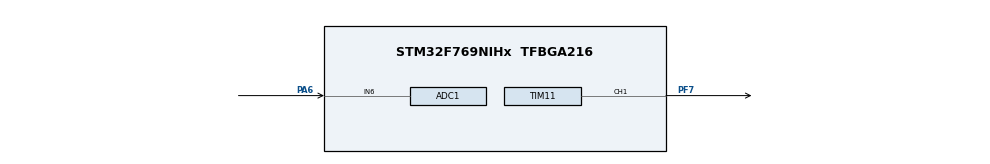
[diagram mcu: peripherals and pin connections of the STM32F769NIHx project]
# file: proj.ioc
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ADC1.Channel-1\#ChannelRegularConversion=ADC_CHANNEL_6
ADC1.NbrOfConversionFlag=1
ADC1.Rank-1\#ChannelRegularConversion=1
ADC1.SamplingTime-1\#ChannelRegularConversion=ADC_SAMPLETIME_3CYCLES
ADC1.master=1
Mcu.Family=STM32F7
Mcu.Name=STM32F769NIHx
Mcu.Package=TFBGA216
NVIC.ADC_IRQn=true\:0\:0\:false\:false\:true\:true\:true
NVIC.PriorityGroup=NVIC_PRIORITYGROUP_4
NVIC.TIM1_TRG_COM_TIM11_IRQn=true\:0\:0\:false\:false\:true\:true\:true
PA6.GPIO_PuPd=GPIO_NOPULL
PA6.Signal=SharedAnalog_PA6
PF7.GPIO_Speed=GPIO_SPEED_FREQ_LOW
PF7.Signal=S_TIM11_CH1
ProjectManager.HeapSize=0x200
ProjectManager.StackSize=0x400
ProjectManager.TargetToolchain=STM32CubeIDE
RCC.HSE_VALUE=25000000
RCC.HSI_VALUE=16000000
RCC.LSE_VALUE=32768
RCC.USBFreq_Value=96000000
RCC.VCOOutputFreq_Value=192000000
SH.S_TIM11_CH1.0=TIM11_CH1,PWM Generation1 CH1
SH.SharedAnalog_PA6.0=GPIO_Analog
SH.SharedAnalog_PA6.1=ADC1_IN6,IN6
TIM11.Channel=TIM_CHANNEL_1
TIM11.Period=100
TIM11.Prescaler=500
VP_TIM11_VS_ClockSourceINT.Mode=Enable_Timer
board=custom

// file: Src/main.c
/* USER CODE BEGIN Header */
/**
  ******************************************************************************
  * @file           : main.c
  * @brief          : Main program body
  ******************************************************************************
  * @attention
  *
  * <h2><center>&copy; Copyright (c) 2019 STMicroelectronics.
  * All rights reserved.</center></h2>
  *
  * This software component is licensed by ST under BSD 3-Clause license,
  * the "License"; You may not use this file except in compliance with the
  * License. You may obtain a copy of the License at:
  *                        opensource.org/licenses/BSD-3-Clause
  *
  ******************************************************************************
  */
/* USER CODE END Header */

#include "main.h"

ADC_HandleTypeDef hadc1;
float dutyCycle;
TIM_HandleTypeDef htim11;

void SystemClock_Config(void);
static void MX_GPIO_Init(void);
static void MX_ADC1_Init(void);
static void MX_TIM11_Init(void);

int main(void)
{

  /* MCU Configuration--------------------------------------------------------*/

  /* Reset of all peripherals, Initializes the Flash interface and the Systick. */
  HAL_Init();

  /* Configure the system clock */
  SystemClock_Config();

  /* Initialize all configured peripherals */
  MX_GPIO_Init();
  MX_ADC1_Init();
  MX_TIM11_Init();

  /* Infinite loop */
  /* USER CODE BEGIN WHILE */
  HAL_TIM_Base_Start_IT(&htim11);
  HAL_ADC_Start_IT(&hadc1);
  HAL_TIM_PWM_Start(&htim11, TIM_CHANNEL_1);
  float aux;
  float adcResult;
  float n;
  while (1)
  {
    /* USER CODE END WHILE */
	  HAL_ADC_Start(&hadc1);
      HAL_ADC_PollForConversion(&hadc1, 100);
	  adcResult = HAL_ADC_GetValue(&hadc1);
      aux=((float)(adcResult-0)/(4095));
	  dutyCycle=1+99*aux;
	   __HAL_TIM_SET_COMPARE(&htim11,TIM_CHANNEL_1,(htim11.Init.Period * dutyCycle) / 100u);
	   //HAL_Delay(100);
  }
}

void SystemClock_Config(void)
{
  RCC_OscInitTypeDef RCC_OscInitStruct = {0};
  RCC_ClkInitTypeDef RCC_ClkInitStruct = {0};

  /** Configure the main internal regulator output voltage
  */
  __HAL_RCC_PWR_CLK_ENABLE();
  __HAL_PWR_VOLTAGESCALING_CONFIG(PWR_REGULATOR_VOLTAGE_SCALE3);
  /** Initializes the CPU, AHB and APB busses clocks
  */
  RCC_OscInitStruct.OscillatorType = RCC_OSCILLATORTYPE_HSI;
  RCC_OscInitStruct.HSIState = RCC_HSI_ON;
  RCC_OscInitStruct.HSICalibrationValue = RCC_HSICALIBRATION_DEFAULT;
  RCC_OscInitStruct.PLL.PLLState = RCC_PLL_NONE;
  if (HAL_RCC_OscConfig(&RCC_OscInitStruct) != HAL_OK)
  {
    Error_Handler();
  }
  /** Initializes the CPU, AHB and APB busses clocks
  */
  RCC_ClkInitStruct.ClockType = RCC_CLOCKTYPE_HCLK|RCC_CLOCKTYPE_SYSCLK
                              |RCC_CLOCKTYPE_PCLK1|RCC_CLOCKTYPE_PCLK2;
  RCC_ClkInitStruct.SYSCLKSource = RCC_SYSCLKSOURCE_HSI;
  RCC_ClkInitStruct.AHBCLKDivider = RCC_SYSCLK_DIV1;
  RCC_ClkInitStruct.APB1CLKDivider = RCC_HCLK_DIV1;
  RCC_ClkInitStruct.APB2CLKDivider = RCC_HCLK_DIV1;

  if (HAL_RCC_ClockConfig(&RCC_ClkInitStruct, FLASH_LATENCY_0) != HAL_OK)
  {
    Error_Handler();
  }
}

static void MX_ADC1_Init(void)
{

  ADC_ChannelConfTypeDef sConfig = {0};

  /** Configure the global features of the ADC (Clock, Resolution, Data Alignment and number of conversion)
  */
  hadc1.Instance = ADC1;
  hadc1.Init.ClockPrescaler = ADC_CLOCK_SYNC_PCLK_DIV2;
  hadc1.Init.Resolution = ADC_RESOLUTION_12B;
  hadc1.Init.ScanConvMode = DISABLE;
  hadc1.Init.ContinuousConvMode = DISABLE;
  hadc1.Init.DiscontinuousConvMode = DISABLE;
  hadc1.Init.ExternalTrigConvEdge = ADC_EXTERNALTRIGCONVEDGE_NONE;
  hadc1.Init.ExternalTrigConv = ADC_SOFTWARE_START;
  hadc1.Init.DataAlign = ADC_DATAALIGN_RIGHT;
  hadc1.Init.NbrOfConversion = 1;
  hadc1.Init.DMAContinuousRequests = DISABLE;
  hadc1.Init.EOCSelection = ADC_EOC_SINGLE_CONV;
  if (HAL_ADC_Init(&hadc1) != HAL_OK)
  {
    Error_Handler();
  }
  /** Configure for the selected ADC regular channel its corresponding rank in the sequencer and its sample time.
  */
  sConfig.Channel = ADC_CHANNEL_6;
  sConfig.Rank = ADC_REGULAR_RANK_1;
  sConfig.SamplingTime = ADC_SAMPLETIME_3CYCLES;
  if (HAL_ADC_ConfigChannel(&hadc1, &sConfig) != HAL_OK)
  {
    Error_Handler();
  }

}

static void MX_TIM11_Init(void)
{

  TIM_OC_InitTypeDef sConfigOC = {0};

  htim11.Instance = TIM11;
  htim11.Init.Prescaler = 7;
  htim11.Init.CounterMode = TIM_COUNTERMODE_UP;
  htim11.Init.Period = 100;
  htim11.Init.ClockDivision = TIM_CLOCKDIVISION_DIV1;
  htim11.Init.AutoReloadPreload = TIM_AUTORELOAD_PRELOAD_DISABLE;
  if (HAL_TIM_Base_Init(&htim11) != HAL_OK)
  {
    Error_Handler();
  }
  if (HAL_TIM_PWM_Init(&htim11) != HAL_OK)
  {
    Error_Handler();
  }
  sConfigOC.OCMode = TIM_OCMODE_PWM1;
  sConfigOC.Pulse = 10;
  sConfigOC.OCPolarity = TIM_OCPOLARITY_HIGH;
  sConfigOC.OCFastMode = TIM_OCFAST_DISABLE;
  if (HAL_TIM_PWM_ConfigChannel(&htim11, &sConfigOC, TIM_CHANNEL_1) != HAL_OK)
  {
    Error_Handler();
  }
  HAL_TIM_MspPostInit(&htim11);

}

static void MX_GPIO_Init(void)
{
  GPIO_InitTypeDef GPIO_InitStruct = {0};

  /* GPIO Ports Clock Enable */
  __HAL_RCC_GPIOF_CLK_ENABLE();
  __HAL_RCC_GPIOA_CLK_ENABLE();

  /*Configure GPIO pin : PA6 */
  GPIO_InitStruct.Pin = GPIO_PIN_6;
  GPIO_InitStruct.Mode = GPIO_MODE_ANALOG;
  GPIO_InitStruct.Pull = GPIO_NOPULL;
  HAL_GPIO_Init(GPIOA, &GPIO_InitStruct);

}

void Error_Handler(void)
{
}

/************************ (C) COPYRIGHT STMicroelectronics *****END OF FILE****/
